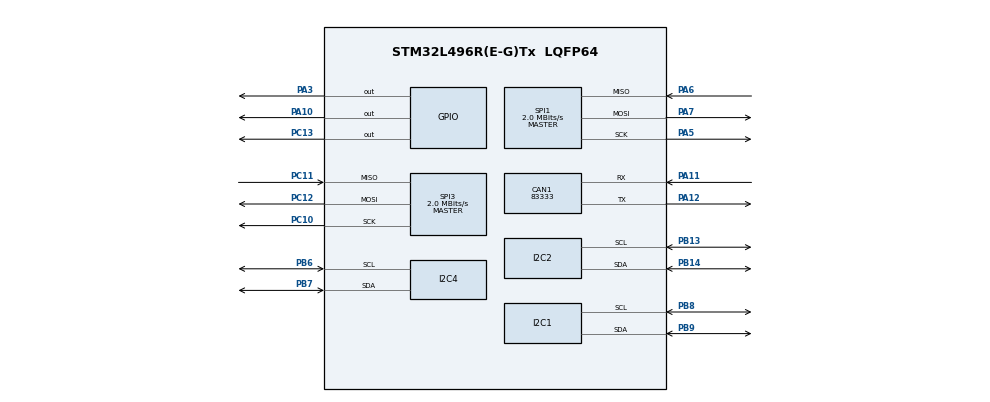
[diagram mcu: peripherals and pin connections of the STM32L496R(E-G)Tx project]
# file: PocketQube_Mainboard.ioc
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CAN1.CalculateBaudRate=83333
CAN1.CalculateTimeBit=12000
CAN1.CalculateTimeQuantum=4000.0
I2C1.Timing=0x00100D14
I2C2.Timing=0x00100D14
I2C4.Timing=0x00100D14
Mcu.Family=STM32L4
Mcu.Name=STM32L496R(E-G)Tx
Mcu.Package=LQFP64
NVIC.PriorityGroup=NVIC_PRIORITYGROUP_4
PA0.Signal=ADCx_IN5
PA1.Signal=ADCx_IN6
PA10.Signal=GPIO_Output
PA11.Mode=CAN_Activate
PA11.Signal=CAN1_RX
PA12.Mode=CAN_Activate
PA12.Signal=CAN1_TX
PA3.Signal=GPIO_Output
PA4.Signal=SPI3_NSS
PA5.Mode=Full_Duplex_Master
PA5.Signal=SPI1_SCK
PA6.Mode=Full_Duplex_Master
PA6.Signal=SPI1_MISO
PA7.Mode=Full_Duplex_Master
PA7.Signal=SPI1_MOSI
PA9.Signal=SPI2_SCK
PB0.Signal=SPI1_NSS
PB12.Signal=SPI2_NSS
PB13.Mode=I2C
PB13.Signal=I2C2_SCL
PB14.Mode=I2C
PB14.Signal=I2C2_SDA
PB3\ (JTDO/TRACESWO).Signal=SYS_JTDO-SWO
PB6.Mode=I2C
PB6.Signal=I2C4_SCL
PB7.Mode=I2C
PB7.Signal=I2C4_SDA
PB8.Mode=I2C
PB8.Signal=I2C1_SCL
PB9.Mode=I2C
PB9.Signal=I2C1_SDA
PC0.Signal=I2C3_SCL
PC1.Signal=I2C3_SDA
PC10.Mode=Full_Duplex_Master
PC10.Signal=SPI3_SCK
PC11.Mode=Full_Duplex_Master
PC11.Signal=SPI3_MISO
PC12.Mode=Full_Duplex_Master
PC12.Signal=SPI3_MOSI
PC13.Signal=GPIO_Output
PC2.Signal=SPI2_MISO
PC3.Signal=SPI2_MOSI
ProjectManager.HeapSize=0x200
ProjectManager.StackSize=0x400
ProjectManager.TargetToolchain=STM32CubeIDE
RCC.HSE_VALUE=8000000
RCC.HSI48_VALUE=48000000
RCC.HSI_VALUE=16000000
RCC.LSE_VALUE=32768
RCC.MSI_VALUE=4000000
RCC.VCOOutputFreq_Value=32000000
SH.ADCx_IN5.0=ADC1_IN5
SH.ADCx_IN6.0=ADC2_IN6
SPI1.CalculateBaudRate=2.0 MBits/s
SPI1.Direction=SPI_DIRECTION_2LINES
SPI1.Mode=SPI_MODE_MASTER
SPI1.VirtualType=VM_MASTER
SPI3.CalculateBaudRate=2.0 MBits/s
SPI3.Direction=SPI_DIRECTION_2LINES
SPI3.Mode=SPI_MODE_MASTER
SPI3.VirtualType=VM_MASTER
board=custom

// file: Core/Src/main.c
/* USER CODE BEGIN Header */
/**
  ******************************************************************************
  * @file           : main.c
  * @brief          : Main program body
  ******************************************************************************
  * @attention
  *
  * Copyright (c) 2026 STMicroelectronics.
  * All rights reserved.
  *
  * This software is licensed under terms that can be found in the LICENSE file
  * in the root directory of this software component.
  * If no LICENSE file comes with this software, it is provided AS-IS.
  *
  ******************************************************************************
  */
/* USER CODE END Header */
#include "main.h"

/* USER CODE BEGIN Includes */
#include <stdio.h>
/* USER CODE END Includes */

CAN_HandleTypeDef hcan1;

I2C_HandleTypeDef hi2c1;
I2C_HandleTypeDef hi2c2;
I2C_HandleTypeDef hi2c4;

SPI_HandleTypeDef hspi1;
SPI_HandleTypeDef hspi3;

void SystemClock_Config(void);
static void MX_GPIO_Init(void);
static void MX_CAN1_Init(void);
static void MX_I2C1_Init(void);
static void MX_I2C2_Init(void);
static void MX_I2C4_Init(void);
static void MX_SPI1_Init(void);
static void MX_SPI3_Init(void);
/* USER CODE BEGIN PFP */
//#define PUTCHAR_PROTOTYPE int __io_putchar(int ch)
/* USER CODE END PFP */

int main(void)
{

  /* MCU Configuration--------------------------------------------------------*/

  /* Reset of all peripherals, Initializes the Flash interface and the Systick. */
  HAL_Init();

  /* Configure the system clock */
  SystemClock_Config();

  /* Initialize all configured peripherals */
  MX_GPIO_Init();
  MX_CAN1_Init();
  MX_I2C1_Init();
  MX_I2C2_Init();
  MX_I2C4_Init();
  MX_SPI1_Init();
  MX_SPI3_Init();

  /* Infinite loop */
  /* USER CODE BEGIN WHILE */

  int count = 0;
  while (1)
  {
	  printf("ciao bella, %d \r \n", count);
	  count++;
	  HAL_Delay(1000);
//	  printf("hello world %d \r\n", count);
//	  count++;
//	  HAL_Delay(1000);
    /* USER CODE END WHILE */

  }
}

void SystemClock_Config(void)
{
  RCC_OscInitTypeDef RCC_OscInitStruct = {0};
  RCC_ClkInitTypeDef RCC_ClkInitStruct = {0};

  /** Configure the main internal regulator output voltage
  */
  if (HAL_PWREx_ControlVoltageScaling(PWR_REGULATOR_VOLTAGE_SCALE1) != HAL_OK)
  {
    Error_Handler();
  }

  /** Initializes the RCC Oscillators according to the specified parameters
  * in the RCC_OscInitTypeDef structure.
  */
  RCC_OscInitStruct.OscillatorType = RCC_OSCILLATORTYPE_MSI;
  RCC_OscInitStruct.MSIState = RCC_MSI_ON;
  RCC_OscInitStruct.MSICalibrationValue = 0;
  RCC_OscInitStruct.MSIClockRange = RCC_MSIRANGE_6;
  RCC_OscInitStruct.PLL.PLLState = RCC_PLL_NONE;
  if (HAL_RCC_OscConfig(&RCC_OscInitStruct) != HAL_OK)
  {
    Error_Handler();
  }

  /** Initializes the CPU, AHB and APB buses clocks
  */
  RCC_ClkInitStruct.ClockType = RCC_CLOCKTYPE_HCLK|RCC_CLOCKTYPE_SYSCLK
                              |RCC_CLOCKTYPE_PCLK1|RCC_CLOCKTYPE_PCLK2;
  RCC_ClkInitStruct.SYSCLKSource = RCC_SYSCLKSOURCE_MSI;
  RCC_ClkInitStruct.AHBCLKDivider = RCC_SYSCLK_DIV1;
  RCC_ClkInitStruct.APB1CLKDivider = RCC_HCLK_DIV1;
  RCC_ClkInitStruct.APB2CLKDivider = RCC_HCLK_DIV1;

  if (HAL_RCC_ClockConfig(&RCC_ClkInitStruct, FLASH_LATENCY_0) != HAL_OK)
  {
    Error_Handler();
  }
}

static void MX_CAN1_Init(void)
{

  hcan1.Instance = CAN1;
  hcan1.Init.Prescaler = 16;
  hcan1.Init.Mode = CAN_MODE_NORMAL;
  hcan1.Init.SyncJumpWidth = CAN_SJW_1TQ;
  hcan1.Init.TimeSeg1 = CAN_BS1_1TQ;
  hcan1.Init.TimeSeg2 = CAN_BS2_1TQ;
  hcan1.Init.TimeTriggeredMode = DISABLE;
  hcan1.Init.AutoBusOff = DISABLE;
  hcan1.Init.AutoWakeUp = DISABLE;
  hcan1.Init.AutoRetransmission = DISABLE;
  hcan1.Init.ReceiveFifoLocked = DISABLE;
  hcan1.Init.TransmitFifoPriority = DISABLE;
  if (HAL_CAN_Init(&hcan1) != HAL_OK)
  {
    Error_Handler();
  }

}

static void MX_I2C1_Init(void)
{

  hi2c1.Instance = I2C1;
  hi2c1.Init.Timing = 0x00100D14;
  hi2c1.Init.OwnAddress1 = 0;
  hi2c1.Init.AddressingMode = I2C_ADDRESSINGMODE_7BIT;
  hi2c1.Init.DualAddressMode = I2C_DUALADDRESS_DISABLE;
  hi2c1.Init.OwnAddress2 = 0;
  hi2c1.Init.OwnAddress2Masks = I2C_OA2_NOMASK;
  hi2c1.Init.GeneralCallMode = I2C_GENERALCALL_DISABLE;
  hi2c1.Init.NoStretchMode = I2C_NOSTRETCH_DISABLE;
  if (HAL_I2C_Init(&hi2c1) != HAL_OK)
  {
    Error_Handler();
  }

  /** Configure Analogue filter
  */
  if (HAL_I2CEx_ConfigAnalogFilter(&hi2c1, I2C_ANALOGFILTER_ENABLE) != HAL_OK)
  {
    Error_Handler();
  }

  /** Configure Digital filter
  */
  if (HAL_I2CEx_ConfigDigitalFilter(&hi2c1, 0) != HAL_OK)
  {
    Error_Handler();
  }

}

static void MX_I2C2_Init(void)
{

  hi2c2.Instance = I2C2;
  hi2c2.Init.Timing = 0x00100D14;
  hi2c2.Init.OwnAddress1 = 0;
  hi2c2.Init.AddressingMode = I2C_ADDRESSINGMODE_7BIT;
  hi2c2.Init.DualAddressMode = I2C_DUALADDRESS_DISABLE;
  hi2c2.Init.OwnAddress2 = 0;
  hi2c2.Init.OwnAddress2Masks = I2C_OA2_NOMASK;
  hi2c2.Init.GeneralCallMode = I2C_GENERALCALL_DISABLE;
  hi2c2.Init.NoStretchMode = I2C_NOSTRETCH_DISABLE;
  if (HAL_I2C_Init(&hi2c2) != HAL_OK)
  {
    Error_Handler();
  }

  /** Configure Analogue filter
  */
  if (HAL_I2CEx_ConfigAnalogFilter(&hi2c2, I2C_ANALOGFILTER_ENABLE) != HAL_OK)
  {
    Error_Handler();
  }

  /** Configure Digital filter
  */
  if (HAL_I2CEx_ConfigDigitalFilter(&hi2c2, 0) != HAL_OK)
  {
    Error_Handler();
  }

}

static void MX_I2C4_Init(void)
{

  hi2c4.Instance = I2C4;
  hi2c4.Init.Timing = 0x00100D14;
  hi2c4.Init.OwnAddress1 = 0;
  hi2c4.Init.AddressingMode = I2C_ADDRESSINGMODE_7BIT;
  hi2c4.Init.DualAddressMode = I2C_DUALADDRESS_DISABLE;
  hi2c4.Init.OwnAddress2 = 0;
  hi2c4.Init.OwnAddress2Masks = I2C_OA2_NOMASK;
  hi2c4.Init.GeneralCallMode = I2C_GENERALCALL_DISABLE;
  hi2c4.Init.NoStretchMode = I2C_NOSTRETCH_DISABLE;
  if (HAL_I2C_Init(&hi2c4) != HAL_OK)
  {
    Error_Handler();
  }

  /** Configure Analogue filter
  */
  if (HAL_I2CEx_ConfigAnalogFilter(&hi2c4, I2C_ANALOGFILTER_ENABLE) != HAL_OK)
  {
    Error_Handler();
  }

  /** Configure Digital filter
  */
  if (HAL_I2CEx_ConfigDigitalFilter(&hi2c4, 0) != HAL_OK)
  {
    Error_Handler();
  }

}

static void MX_SPI1_Init(void)
{

  /* SPI1 parameter configuration*/
  hspi1.Instance = SPI1;
  hspi1.Init.Mode = SPI_MODE_MASTER;
  hspi1.Init.Direction = SPI_DIRECTION_2LINES;
  hspi1.Init.DataSize = SPI_DATASIZE_4BIT;
  hspi1.Init.CLKPolarity = SPI_POLARITY_LOW;
  hspi1.Init.CLKPhase = SPI_PHASE_1EDGE;
  hspi1.Init.NSS = SPI_NSS_SOFT;
  hspi1.Init.BaudRatePrescaler = SPI_BAUDRATEPRESCALER_2;
  hspi1.Init.FirstBit = SPI_FIRSTBIT_MSB;
  hspi1.Init.TIMode = SPI_TIMODE_DISABLE;
  hspi1.Init.CRCCalculation = SPI_CRCCALCULATION_DISABLE;
  hspi1.Init.CRCPolynomial = 7;
  hspi1.Init.CRCLength = SPI_CRC_LENGTH_DATASIZE;
  hspi1.Init.NSSPMode = SPI_NSS_PULSE_ENABLE;
  if (HAL_SPI_Init(&hspi1) != HAL_OK)
  {
    Error_Handler();
  }

}

static void MX_SPI3_Init(void)
{

  /* SPI3 parameter configuration*/
  hspi3.Instance = SPI3;
  hspi3.Init.Mode = SPI_MODE_MASTER;
  hspi3.Init.Direction = SPI_DIRECTION_2LINES;
  hspi3.Init.DataSize = SPI_DATASIZE_4BIT;
  hspi3.Init.CLKPolarity = SPI_POLARITY_LOW;
  hspi3.Init.CLKPhase = SPI_PHASE_1EDGE;
  hspi3.Init.NSS = SPI_NSS_SOFT;
  hspi3.Init.BaudRatePrescaler = SPI_BAUDRATEPRESCALER_2;
  hspi3.Init.FirstBit = SPI_FIRSTBIT_MSB;
  hspi3.Init.TIMode = SPI_TIMODE_DISABLE;
  hspi3.Init.CRCCalculation = SPI_CRCCALCULATION_DISABLE;
  hspi3.Init.CRCPolynomial = 7;
  hspi3.Init.CRCLength = SPI_CRC_LENGTH_DATASIZE;
  hspi3.Init.NSSPMode = SPI_NSS_PULSE_ENABLE;
  if (HAL_SPI_Init(&hspi3) != HAL_OK)
  {
    Error_Handler();
  }

}

static void MX_GPIO_Init(void)
{
  GPIO_InitTypeDef GPIO_InitStruct = {0};

  /* GPIO Ports Clock Enable */
  __HAL_RCC_GPIOC_CLK_ENABLE();
  __HAL_RCC_GPIOA_CLK_ENABLE();
  __HAL_RCC_GPIOB_CLK_ENABLE();

  /*Configure GPIO pin Output Level */
  HAL_GPIO_WritePin(GPIOC, GPIO_PIN_13, GPIO_PIN_RESET);

  /*Configure GPIO pin Output Level */
  HAL_GPIO_WritePin(GPIOA, GPIO_PIN_3|GPIO_PIN_10, GPIO_PIN_RESET);

  /*Configure GPIO pin : PC13 */
  GPIO_InitStruct.Pin = GPIO_PIN_13;
  GPIO_InitStruct.Mode = GPIO_MODE_OUTPUT_PP;
  GPIO_InitStruct.Pull = GPIO_NOPULL;
  GPIO_InitStruct.Speed = GPIO_SPEED_FREQ_LOW;
  HAL_GPIO_Init(GPIOC, &GPIO_InitStruct);

  /*Configure GPIO pins : PC0 PC1 */
  GPIO_InitStruct.Pin = GPIO_PIN_0|GPIO_PIN_1;
  GPIO_InitStruct.Mode = GPIO_MODE_AF_OD;
  GPIO_InitStruct.Pull = GPIO_NOPULL;
  GPIO_InitStruct.Speed = GPIO_SPEED_FREQ_VERY_HIGH;
  GPIO_InitStruct.Alternate = GPIO_AF4_I2C3;
  HAL_GPIO_Init(GPIOC, &GPIO_InitStruct);

  /*Configure GPIO pins : PC2 PC3 */
  GPIO_InitStruct.Pin = GPIO_PIN_2|GPIO_PIN_3;
  GPIO_InitStruct.Mode = GPIO_MODE_AF_PP;
  GPIO_InitStruct.Pull = GPIO_NOPULL;
  GPIO_InitStruct.Speed = GPIO_SPEED_FREQ_VERY_HIGH;
  GPIO_InitStruct.Alternate = GPIO_AF5_SPI2;
  HAL_GPIO_Init(GPIOC, &GPIO_InitStruct);

  /*Configure GPIO pins : PA0 PA1 */
  GPIO_InitStruct.Pin = GPIO_PIN_0|GPIO_PIN_1;
  GPIO_InitStruct.Mode = GPIO_MODE_ANALOG;
  GPIO_InitStruct.Pull = GPIO_NOPULL;
  HAL_GPIO_Init(GPIOA, &GPIO_InitStruct);

  /*Configure GPIO pins : PA3 PA10 */
  GPIO_InitStruct.Pin = GPIO_PIN_3|GPIO_PIN_10;
  GPIO_InitStruct.Mode = GPIO_MODE_OUTPUT_PP;
  GPIO_InitStruct.Pull = GPIO_NOPULL;
  GPIO_InitStruct.Speed = GPIO_SPEED_FREQ_LOW;
  HAL_GPIO_Init(GPIOA, &GPIO_InitStruct);

  /*Configure GPIO pin : PB12 */
  GPIO_InitStruct.Pin = GPIO_PIN_12;
  GPIO_InitStruct.Mode = GPIO_MODE_AF_PP;
  GPIO_InitStruct.Pull = GPIO_NOPULL;
  GPIO_InitStruct.Speed = GPIO_SPEED_FREQ_VERY_HIGH;
  GPIO_InitStruct.Alternate = GPIO_AF5_SPI2;
  HAL_GPIO_Init(GPIOB, &GPIO_InitStruct);

  /*Configure GPIO pin : PA9 */
  GPIO_InitStruct.Pin = GPIO_PIN_9;
  GPIO_InitStruct.Mode = GPIO_MODE_AF_PP;
  GPIO_InitStruct.Pull = GPIO_NOPULL;
  GPIO_InitStruct.Speed = GPIO_SPEED_FREQ_VERY_HIGH;
  GPIO_InitStruct.Alternate = GPIO_AF3_SPI2;
  HAL_GPIO_Init(GPIOA, &GPIO_InitStruct);

}

/* USER CODE BEGIN 4 */

/**
 * @brief Retargets the C library printf function to the USART.
 * None
 * @retval None
 */
//PUTCHAR_PROTOTYPE
//{
// /* Place your implementation of fputc here */
// /* e.g. write a character to the USART1 and Loop until the end of transmission */
// HAL_UART_Transmit(&huart2, (uint8_t *)&ch, 1, 0xFFFF);
// return ch;
//}

/* USER CODE END 4 */

void Error_Handler(void)
{
  __disable_irq();
  while (1)
  {
  }
}
